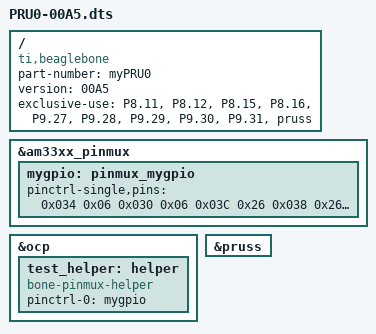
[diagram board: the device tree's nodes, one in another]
/dts-v1/;
/plugin/;

/ {
  compatible = "ti,beaglebone", "ti,beaglebone-black";

  part-number = "myPRU0";
  version = "00A5";

  exclusive-use =
    "P8.11",
    "P8.12",
    "P8.15",
    "P8.16",
    "P9.27",
    "P9.28",
    "P9.29",
    "P9.30",
    "P9.31",
    "pruss";

  fragment@0 {
    target = <&am33xx_pinmux>;
    __overlay__ {
      mygpio: pinmux_mygpio{
        pinctrl-single,pins = <
          0x034 0x06
          0x030 0x06
          0x03C 0x26
          0x038 0x26
          0x1A4 0x26
          0x19C 0x26
          0x194 0x26
          0x198 0x26
          0x190 0x26
         >;
      };
    };
  };

  fragment@1 {
    target = <&ocp>;
    __overlay__ {
      test_helper: helper {
        compatible = "bone-pinmux-helper";
        pinctrl-names = "default";
        pinctrl-0 = <&mygpio>;
        status = "okay";
      };
    };
  };

  fragment@2{
  target = <&pruss>;
   __overlay__ {
     status = "okay";
   };
  };
};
